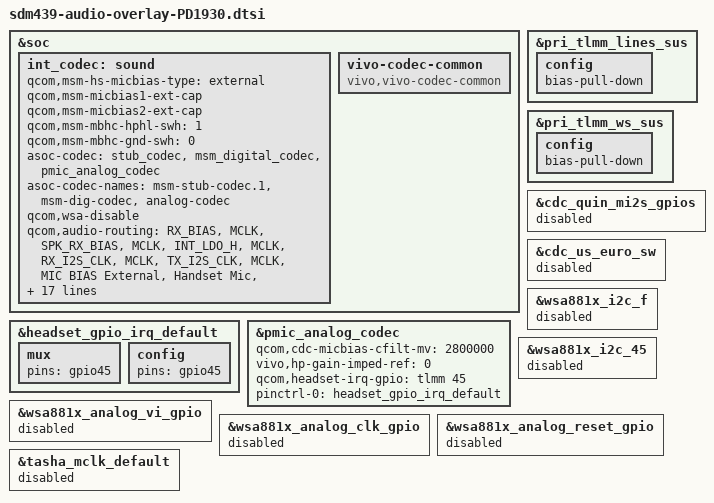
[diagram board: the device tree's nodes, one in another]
/*
 * Copyright (c) 2018, The Linux Foundation. All rights reserved.
 *
 * This program is free software; you can redistribute it and/or modify
 * it under the terms of the GNU General Public License version 2 and
 * only version 2 as published by the Free Software Foundation.
 *
 * This program is distributed in the hope that it will be useful,
 * but WITHOUT ANY WARRANTY; without even the implied warranty of
 * MERCHANTABILITY or FITNESS FOR A PARTICULAR PURPOSE.  See the
 * GNU General Public License for more details.
 */

&soc {
	int_codec: sound {
		qcom,msm-hs-micbias-type = "external";

		qcom,msm-micbias1-ext-cap;
		qcom,msm-micbias2-ext-cap;

		qcom,msm-mbhc-hphl-swh = <1>;
		qcom,msm-mbhc-gnd-swh = <0>;

		asoc-codec = <&stub_codec>, <&msm_digital_codec>,
				<&pmic_analog_codec>;
		asoc-codec-names = "msm-stub-codec.1", "msm-dig-codec",
					"analog-codec";

		qcom,wsa-disable;

		/delete-property/ msm-vdd-wsa-switch-supply;
		/delete-property/ qcom,msm-vdd-wsa-switch-voltage;
		/delete-property/ qcom,msm-vdd-wsa-switch-current;

		/delete-property/ qcom,cdc-us-euro-gpios;
		/delete-property/ qcom,cdc-us-eu-gpios;
		/delete-property/ qcom,quin-mi2s-gpios;

		qcom,audio-routing =
				"RX_BIAS", "MCLK",
				"SPK_RX_BIAS", "MCLK",
				"INT_LDO_H", "MCLK",
				"RX_I2S_CLK", "MCLK",
				"TX_I2S_CLK", "MCLK",
				"MIC BIAS External", "Handset Mic",
				"MIC BIAS External2", "Headset Mic",
				"MIC BIAS External", "Secondary Mic",
				"AMIC1", "MIC BIAS External",
				"AMIC2", "MIC BIAS External2",
				"AMIC3", "MIC BIAS External",
				"ADC1_IN", "ADC1_OUT",
				"ADC2_IN", "ADC2_OUT",
				"ADC3_IN", "ADC3_OUT",
				"PDM_IN_RX1", "PDM_OUT_RX1",
				"PDM_IN_RX2", "PDM_OUT_RX2",
				"PDM_IN_RX3", "PDM_OUT_RX3";

		ext-spkamp-gpio = <&tlmm 20 0>;
		vivo,aw87318_work_mode = <3>;

		vivo,builtin-mic-num = <1>;
		vivo,fm-support;
		vivo,fm-hostless-pcm-spk = <5>;
		vivo,fm-hostless-pcm-hp = <5>;
		vivo,mbhc-imped-adjust-ref = <10>;
		vivo,mbhc-btn-defs = <60 100 235 460 460
			60 100 235 460 460>;
	};
};

&soc {
	vivo-codec-common {
		compatible = "vivo,vivo-codec-common";
	};
};

&headset_gpio_irq_default {
    mux {
        pins = "gpio45";
    };

    config {
        pins = "gpio45";
    };
};

&pmic_analog_codec {
	qcom,cdc-micbias-cfilt-mv = <2800000>;
	vivo,hp-gain-imped-ref = <0>;
	qcom,headset-irq-gpio = <&tlmm 45 0>;
	pinctrl-names = "headset_gpio_irq";
	pinctrl-0 =  <&headset_gpio_irq_default>;
};

&pri_tlmm_lines_sus {
    config {
        bias-pull-down;
    };
};

&pri_tlmm_ws_sus {
    config {
        bias-pull-down;
    };
};

&cdc_quin_mi2s_gpios {
	status = "disabled";
};

&cdc_us_euro_sw {
	status = "disabled";
};

&wsa881x_i2c_f {
	status = "disabled";
};

&wsa881x_i2c_45 {
	status = "disabled";
};

&wsa881x_analog_vi_gpio {
	status = "disabled";
};

&wsa881x_analog_clk_gpio {
	status = "disabled";
};

&wsa881x_analog_reset_gpio {
	status = "disabled";
};

&tasha_mclk_default {
	status = "disabled";
};
